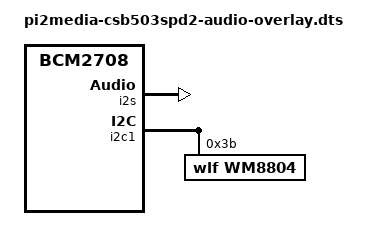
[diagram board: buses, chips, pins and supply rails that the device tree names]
// Definitions for P2Media CSB503SPD2
/dts-v1/;
/plugin/;

/ {
	compatible = "brcm,bcm2708";

	fragment@0 {
		target = <&i2s>;
		__overlay__ {
			status = "okay";
		};
	};

	fragment@1 {
		target = <&i2c1>;
		__overlay__ {
			#address-cells = <1>;
			#size-cells = <0>;
			status = "okay";

			wm8804@3b {
				#sound-dai-cells = <0>;
				compatible = "wlf,wm8804";
				reg = <0x3b>;
				status = "okay";
			};
		};
	};

	fragment@2 {
		target = <&sound>;
		__overlay__ {
			compatible = "pi2media,pi2media-csb503spd2-audio";
			i2s-controller = <&i2s>;
			status = "okay";
		};
	};
};
